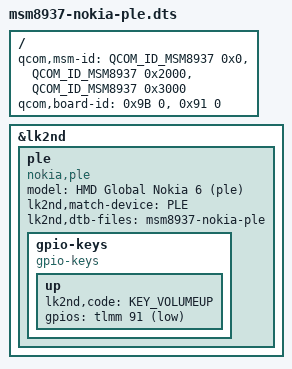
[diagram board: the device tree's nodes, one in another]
// SPDX-License-Identifier: BSD-3-Clause

#include <skeleton64.dtsi>
#include <lk2nd.dtsi>

/ {
	qcom,msm-id = 	<QCOM_ID_MSM8937 0x0>,	  // Variant: FIH_PLE_EVT1 / FIH_D1C_EVT1
			<QCOM_ID_MSM8937 0x2000>, // Variant: FIH_PLE_DVT1 / FIH_D1C_DVT1
			<QCOM_ID_MSM8937 0x3000>; // Variant: FIH_PLE_PVT / FIH_D1C_PVT
	qcom,board-id = <0x9B 0>, // PLE (Global version)
			<0x91 0>; // D1C (China version)
};

&lk2nd {
	ple {
		model = "HMD Global Nokia 6 (ple)";
		compatible = "nokia,ple";
		lk2nd,match-device = "PLE";

		lk2nd,dtb-files = "msm8937-nokia-ple";

		gpio-keys {
			compatible = "gpio-keys";
			up {
				lk2nd,code = <KEY_VOLUMEUP>;
				gpios = <&tlmm 91 (GPIO_ACTIVE_LOW | GPIO_PULL_UP)>;
			};
		};
	};
};
